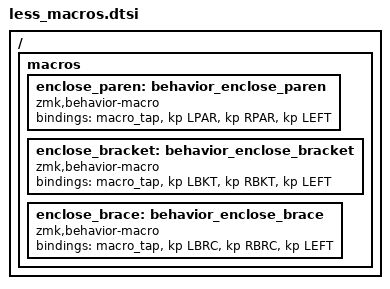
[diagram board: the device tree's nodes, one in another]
/*
 * Copyright (c) 2023 The ZMK Contributors
 *
 * SPDX-License-Identifier: MIT
 */

/ {
    macros {
        enclose_paren: behavior_enclose_paren {
            compatible = "zmk,behavior-macro";
            #binding-cells = <0>;
            bindings
                = <&macro_tap &kp LPAR &kp RPAR &kp LEFT>
                ;
        };
        enclose_bracket: behavior_enclose_bracket {
            compatible = "zmk,behavior-macro";
            #binding-cells = <0>;
            bindings
                = <&macro_tap &kp LBKT &kp RBKT &kp LEFT>
                ;
        };
        enclose_brace: behavior_enclose_brace {
            compatible = "zmk,behavior-macro";
            #binding-cells = <0>;
            bindings
                = <&macro_tap &kp LBRC &kp RBRC &kp LEFT>
                ;
        };
    };
};
